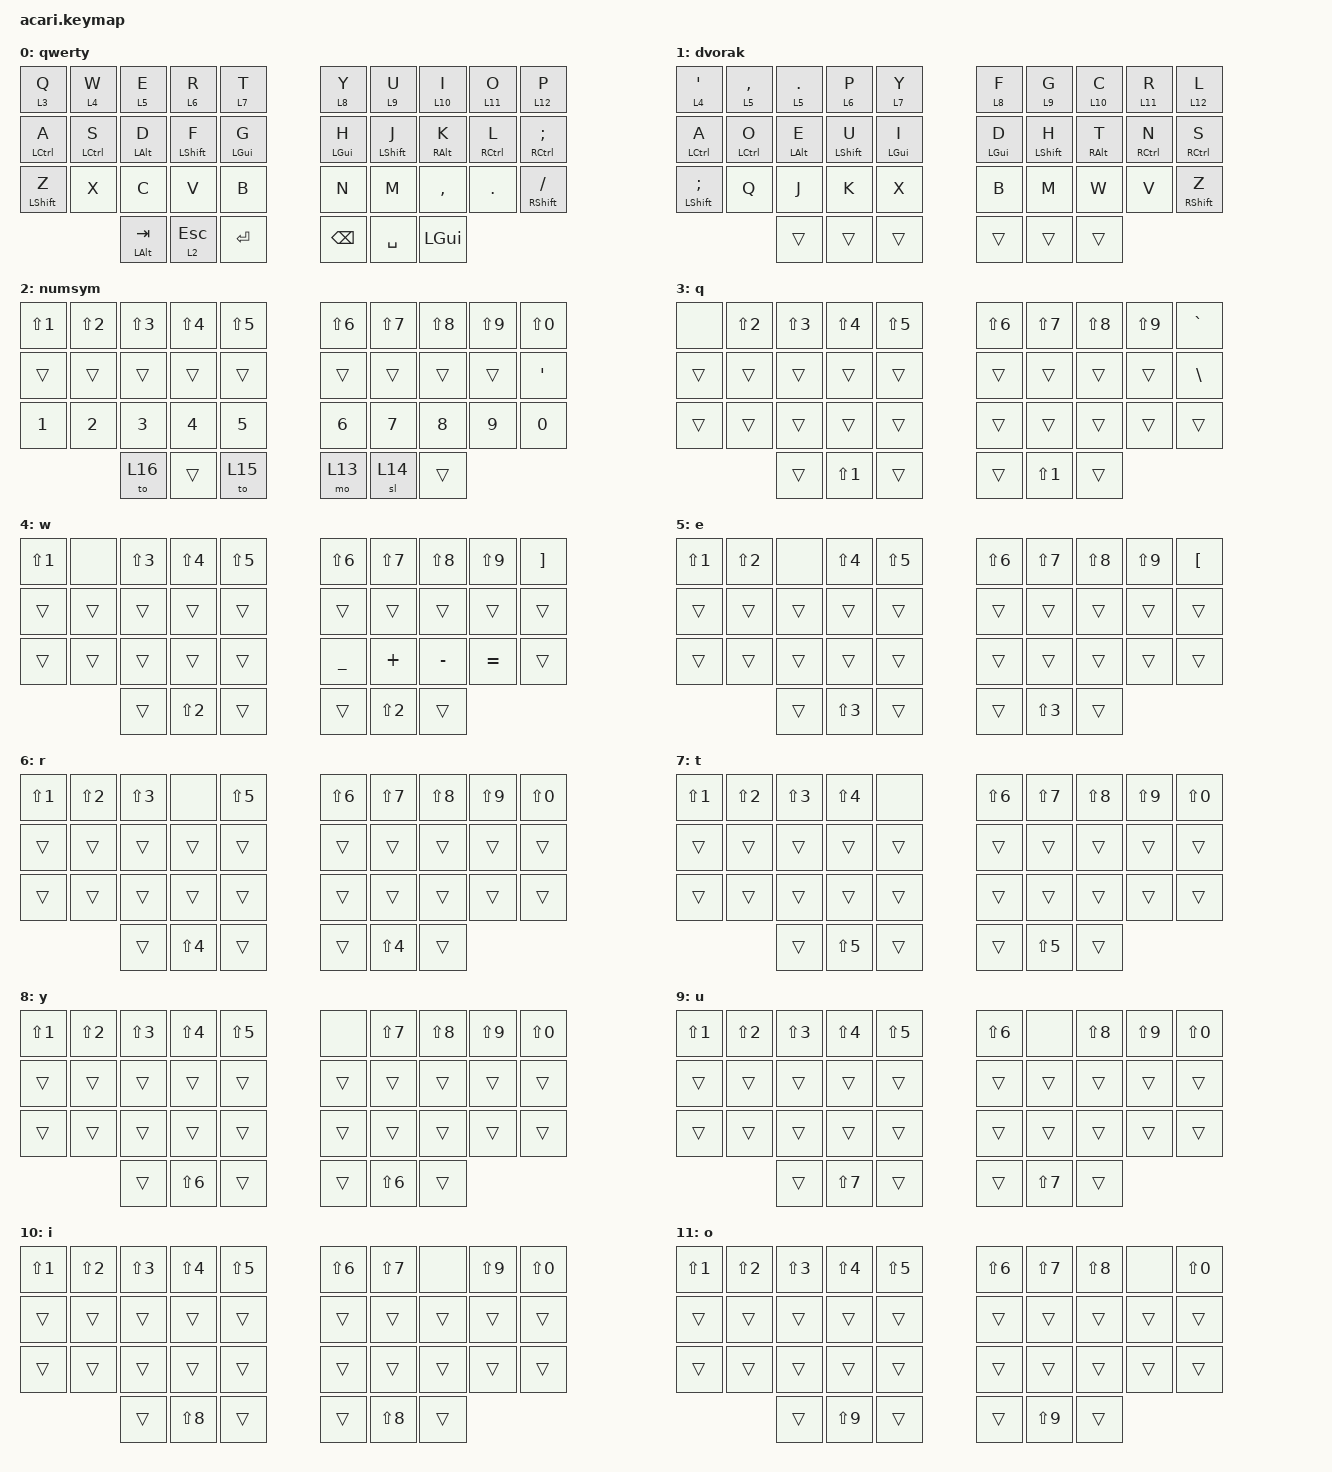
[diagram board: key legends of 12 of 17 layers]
#include <behaviors.dtsi>
#include <dt-bindings/zmk/bt.h>
#include <dt-bindings/zmk/keys.h>

#define BASE 0
#define NAV  1
#define NUM  2
#define FUN  3
#define SYM  4
#define MEDIA  5
#define BLU 6

/*                KEY POSITIONS

          ╭────────────────────╮ ╭────────────────────╮
          │  0   1   2   3   4 │ │  5   6   7   8   9 │
          │ 10  11  12  13  14 │ │ 15  16  17  18  19 │
          │ 20  21  22  23  24 │ │ 25  26  27  28  29 │
          ╰───────╮ 30  31  32 │ │ 33  34  35 ╭───────╯
                  ╰────────────╯ ╰────────────╯        */

&mt {
    flavor = "balanced";
    retro-tap;
    require-prior-idle-ms = <120>;
};

&lt {
    flavor = "balanced";
    retro-tap;
    require-prior-idle-ms = <120>;
};

/ {
    combos {
        compatible = "zmk,combos";

        leftParet {
            bindings = <&kp LEFT_PARENTHESIS>;
            key-positions = <6 7>;
        };

        rightParet {
            bindings = <&kp RIGHT_PARENTHESIS>;
            key-positions = <7 8>;
        };

        minusCombo {
            bindings = <&kp MINUS>;
            key-positions = <32 33>;
        };

        capslock {
            bindings = <&caps_word>;
            key-positions = <4 5>;
        };

        printscreen {
            bindings = <&kp LG(LS(N5))>;
            key-positions = <1 2 3>;
            timeout-ms = <40>;
        };

        apost {
            bindings = <&kp APOSTROPHE>;
            key-positions = <14 15>;
        };

        c1 {
            bindings = <&kp NUMBER_1>;
            key-positions = <0 31>;
        };
    };

    behaviors {
        rht: repeatHoldTap {
            compatible = "zmk,behavior-hold-tap";
            label = "REPEATHOLDTAP";
            bindings = <&mo>, <&kp>;

            #binding-cells = <2>;
            flavor = "balanced";
            tapping-term-ms = <120>;
            quick-tap-ms = <200>;
            retro-tap;
            require-prior-idle-ms = <120>;
        };
    };

    macros {
        euro: euro {
            compatible = "zmk,behavior-macro";
            #binding-cells = <0>;
            bindings = <&kp LA(NUMBER_0) &kp LA(NUMBER_1) &kp LA(NUMBER_2) &kp LA(N8)>;
            label = "EURO";
        };
    };

    keymap {
        compatible = "zmk,keymap";

        qwerty {
            bindings = <
&lt 3 Q             &lt 4 W      &lt 5 E           &lt 6 R       &lt 7 T         &lt 8 Y         &lt 9 U       &lt 10 I      &lt 11 O             &lt 12 P
&mt LEFT_CONTROL A  &mt LCTRL S  &mt LEFT_ALT D    &mt LSHIFT F  &mt LEFT_GUI G  &mt LEFT_GUI H  &mt LSHIFT J  &mt RALT K    &mt RIGHT_CONTROL L  &mt RIGHT_CONTROL SEMICOLON
&mt LEFT_SHIFT Z    &kp X        &kp C             &kp V         &kp B           &kp N           &kp M         &kp COMMA     &kp PERIOD           &mt RSHIFT SLASH
                                 &mt LEFT_ALT TAB  &lt 2 ESCAPE  &kp ENTER       &kp BSPC        &kp SPACE     &kp LEFT_GUI
            >;
        };

        dvorak {
            bindings = <
&lt 4 SINGLE_QUOTE        &lt 5 COMMA  &lt 5 PERIOD    &lt 6 P       &lt 7 Y         &lt 8 F         &lt 9 G       &lt 10 C    &lt 11 R             &lt 12 L
&mt LEFT_CONTROL A        &mt LCTRL O  &mt LEFT_ALT E  &mt LSHIFT U  &mt LEFT_GUI I  &mt LEFT_GUI D  &mt LSHIFT H  &mt RALT T  &mt RIGHT_CONTROL N  &mt RIGHT_CONTROL S
&mt LEFT_SHIFT SEMICOLON  &kp Q        &kp J           &kp K         &kp X           &kp B           &kp M         &kp W       &kp V                &mt RSHIFT Z
                                       &trans          &trans        &trans          &trans          &trans        &trans
            >;
        };

        numsym {
            bindings = <
&kp LS(N1)  &kp LS(N2)  &kp LS(N3)  &kp LS(N4)  &kp LS(N5)  &kp LS(N6)  &kp LS(N7)  &kp LS(N8)  &kp LS(N9)  &kp LS(N0)
&trans      &trans      &trans      &trans      &trans      &trans      &trans      &trans      &trans      &kp APOSTROPHE
&kp N1      &kp N2      &kp N3      &kp N4      &kp N5      &kp N6      &kp N7      &kp N8      &kp N9      &kp N0
                        &to 16      &trans      &to 15      &mo 13      &sl 14      &trans
            >;
        };

        q {
            bindings = <
&none   &kp LS(N2)  &kp LS(N3)  &kp LS(N4)        &kp LS(N5)  &kp LS(N6)  &kp LS(N7)        &kp LS(N8)  &kp LS(N9)  &kp GRAVE
&trans  &trans      &trans      &trans            &trans      &trans      &trans            &trans      &trans      &kp BACKSLASH
&trans  &trans      &trans      &trans            &trans      &trans      &trans            &trans      &trans      &trans
                    &trans      &kp LS(NUMBER_1)  &trans      &trans      &kp LS(NUMBER_1)  &trans
            >;
        };

        w {
            bindings = <
&kp LS(N1)  &none   &kp LS(N3)  &kp LS(N4)        &kp LS(N5)  &kp LS(N6)  &kp LS(N7)        &kp LS(N8)  &kp LS(N9)  &kp RIGHT_BRACKET
&trans      &trans  &trans      &trans            &trans      &trans      &trans            &trans      &trans      &trans
&trans      &trans  &trans      &trans            &trans      &kp UNDER   &kp PLUS          &kp MINUS   &kp EQUAL   &trans
                    &trans      &kp LS(NUMBER_2)  &trans      &trans      &kp LS(NUMBER_2)  &trans
            >;
        };

        e {
            bindings = <
&kp LS(N1)  &kp LS(N2)  &none   &kp LS(N4)        &kp LS(N5)  &kp LS(N6)  &kp LS(N7)        &kp LS(N8)  &kp LS(N9)  &kp LEFT_BRACKET
&trans      &trans      &trans  &trans            &trans      &trans      &trans            &trans      &trans      &trans
&trans      &trans      &trans  &trans            &trans      &trans      &trans            &trans      &trans      &trans
                        &trans  &kp LS(NUMBER_3)  &trans      &trans      &kp LS(NUMBER_3)  &trans
            >;
        };

        r {
            bindings = <
&kp LS(N1)  &kp LS(N2)  &kp LS(N3)  &none             &kp LS(N5)  &kp LS(N6)  &kp LS(N7)        &kp LS(N8)  &kp LS(N9)  &kp LS(N0)
&trans      &trans      &trans      &trans            &trans      &trans      &trans            &trans      &trans      &trans
&trans      &trans      &trans      &trans            &trans      &trans      &trans            &trans      &trans      &trans
                        &trans      &kp LS(NUMBER_4)  &trans      &trans      &kp LS(NUMBER_4)  &trans
            >;
        };

        t {
            bindings = <
&kp LS(N1)  &kp LS(N2)  &kp LS(N3)  &kp LS(N4)  &none   &kp LS(N6)  &kp LS(N7)  &kp LS(N8)  &kp LS(N9)  &kp LS(N0)
&trans      &trans      &trans      &trans      &trans  &trans      &trans      &trans      &trans      &trans
&trans      &trans      &trans      &trans      &trans  &trans      &trans      &trans      &trans      &trans
                        &trans      &kp LS(N5)  &trans  &trans      &kp LS(N5)  &trans
            >;
        };

        y {
            bindings = <
&kp LS(N1)  &kp LS(N2)  &kp LS(N3)  &kp LS(N4)        &kp LS(N5)  &none   &kp LS(N7)        &kp LS(N8)  &kp LS(N9)  &kp LS(N0)
&trans      &trans      &trans      &trans            &trans      &trans  &trans            &trans      &trans      &trans
&trans      &trans      &trans      &trans            &trans      &trans  &trans            &trans      &trans      &trans
                        &trans      &kp LS(NUMBER_6)  &trans      &trans  &kp LS(NUMBER_6)  &trans
            >;
        };

        u {
            bindings = <
&kp LS(N1)  &kp LS(N2)  &kp LS(N3)  &kp LS(N4)  &kp LS(N5)  &kp LS(N6)  &none       &kp LS(N8)  &kp LS(N9)  &kp LS(N0)
&trans      &trans      &trans      &trans      &trans      &trans      &trans      &trans      &trans      &trans
&trans      &trans      &trans      &trans      &trans      &trans      &trans      &trans      &trans      &trans
                        &trans      &kp LS(N7)  &trans      &trans      &kp LS(N7)  &trans
            >;
        };

        i {
            bindings = <
&kp LS(N1)  &kp LS(N2)  &kp LS(N3)  &kp LS(N4)  &kp LS(N5)  &kp LS(N6)  &kp LS(N7)  &none   &kp LS(N9)  &kp LS(N0)
&trans      &trans      &trans      &trans      &trans      &trans      &trans      &trans  &trans      &trans
&trans      &trans      &trans      &trans      &trans      &trans      &trans      &trans  &trans      &trans
                        &trans      &kp LS(N8)  &trans      &trans      &kp LS(N8)  &trans
            >;
        };

        o {
            bindings = <
&kp LS(N1)  &kp LS(N2)  &kp LS(N3)  &kp LS(N4)  &kp LS(N5)  &kp LS(N6)  &kp LS(N7)  &kp LS(N8)  &none   &kp LS(N0)
&trans      &trans      &trans      &trans      &trans      &trans      &trans      &trans      &trans  &trans
&trans      &trans      &trans      &trans      &trans      &trans      &trans      &trans      &trans  &trans
                        &trans      &kp LS(N9)  &trans      &trans      &kp LS(N9)  &trans
            >;
        };

        p {
            bindings = <
&kp LS(N1)  &kp LS(N2)  &kp LS(N3)  &kp LS(N4)  &kp LS(N5)  &kp LS(N6)  &kp LS(N7)  &kp LS(N8)  &kp LS(N9)  &none
&trans      &trans      &trans      &trans      &trans      &trans      &trans      &trans      &trans      &trans
&trans      &trans      &trans      &trans      &trans      &trans      &trans      &trans      &trans      &trans
                        &trans      &kp LS(N0)  &trans      &trans      &kp LS(N0)  &trans
            >;
        };

        media {
            bindings = <
&trans        &trans        &trans        &trans  &trans          &kp PRINTSCREEN  &trans             &none            &trans      &studio_unlock
&trans        &trans        &trans        &trans  &bt BT_CLR_ALL  &kp C_PREVIOUS   &kp C_VOLUME_DOWN  &kp C_VOLUME_UP  &kp C_NEXT  &trans
&bt BT_SEL 0  &bt BT_SEL 1  &bt BT_SEL 2  &trans  &bt BT_CLR      &trans           &trans             &kp C_MUTE       &trans      &trans
                            &trans        &trans  &trans          &kp C_STOP       &kp C_PLAY_PAUSE   &kp K_MUTE
            >;
        };

        nav {
            bindings = <
&trans  &kp F1  &kp F2   &kp F3   &trans   &kp N6         &kp N7    &kp UP_ARROW    &kp N9     &kp N0
&trans  &kp F4  &kp F5   &kp F6   &trans   &kp PG_UP      &kp LEFT  &kp DOWN_ARROW  &kp RIGHT  &trans
&trans  &kp F7  &kp F8   &kp F9   &trans   &kp PAGE_DOWN  &trans    &trans          &trans     &trans
                &kp F10  &kp F11  &kp F12  &trans         &trans    &kp DELETE
            >;
        };

        rqwerty {
            bindings = <
&kp X     &kp COMMA  &kp D      &kp O           &kp K      &kp T       &kp F    &kp G  &kp S  &kp R
&kp A     &kp SEMI   &kp H      &kp Y           &kp U      &kp J       &kp C    &kp V  &kp P  &kp Z
&kp FSLH  &kp B      &kp I      &kp DOT         &kp N      &kp L       &kp M    &kp W  &kp E  &kp LBKT
                     &kp SPACE  &kp LEFT_SHIFT  &kp LCTRL  &kp ESCAPE  &kp TAB  &to 0
            >;
        };

        valheim {
            bindings = <
&kp X     &kp COMMA  &kp D      &kp O           &kp K      &kp T       &kp N1   &kp N2  &kp N3  &kp R
&kp A     &kp SEMI   &kp H      &kp Y           &kp U      &kp J       &kp N4   &kp N5  &kp N6  &kp Z
&kp FSLH  &kp B      &kp I      &kp DOT         &kp N      &kp L       &kp N7   &kp N8  &kp N9  &kp LBKT
                     &kp SPACE  &kp LEFT_SHIFT  &kp LCTRL  &kp ESCAPE  &kp TAB  &to 0
            >;
        };
    };
};
